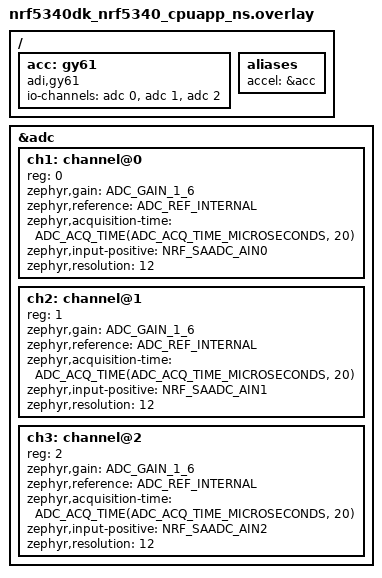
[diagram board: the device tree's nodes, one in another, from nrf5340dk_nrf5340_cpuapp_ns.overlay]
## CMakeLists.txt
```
cmake_minimum_required(VERSION 3.20.0)

find_package(Zephyr REQUIRED HINTS $ENV{ZEPHYR_BASE})

project(accel_sensor)

target_sources(app PRIVATE src/main.c)
target_sources(app PRIVATE src/acc_service.c)
target_sources(app PRIVATE src/acc_sensor.c)

# Please let this help with the sensor devicetree
set (DTS_ROOT "dts")
```

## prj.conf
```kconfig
CONFIG_SENSOR=y
CONFIG_DK_LIBRARY=y
#CONFIG_ADXL355=y

CONFIG_LOG=y
CONFIG_CBPRINTF_FP_SUPPORT=y

CONFIG_BT=y
CONFIG_BT_PERIPHERAL=y
CONFIG_BT_DEVICE_NAME="Accelerometer"

CONFIG_SYSTEM_WORKQUEUE_STACK_SIZE=2048
CONFIG_MAIN_STACK_SIZE=2048
```

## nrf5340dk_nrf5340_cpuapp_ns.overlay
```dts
// help I'm lost

/ {
    acc: gy61 {
        status = "okay";
        compatible = "adi,gy61";
        //label = "gy61";
        io-channels = <&adc 0>, <&adc 1>, <&adc 2>;
    };

    aliases {
        accel = &acc;
    };
};

&adc {
    status = "okay";
    #address-cells = <1>;
    #size-cells = <0>;

    ch1: channel@0 {
        status = "okay";
        reg = <0>;
        zephyr,gain = "ADC_GAIN_1_6";
        zephyr,reference = "ADC_REF_INTERNAL";
        zephyr,acquisition-time = <ADC_ACQ_TIME(ADC_ACQ_TIME_MICROSECONDS, 20)>;
        zephyr,input-positive = <NRF_SAADC_AIN0>;
        zephyr,resolution = <12>;
    };

    ch2: channel@1 {
        status = "okay";
        reg = <1>;
        zephyr,gain = "ADC_GAIN_1_6";
        zephyr,reference = "ADC_REF_INTERNAL";
        zephyr,acquisition-time = <ADC_ACQ_TIME(ADC_ACQ_TIME_MICROSECONDS, 20)>;
        zephyr,input-positive = <NRF_SAADC_AIN1>;
        zephyr,resolution = <12>;
    };

    ch3: channel@2 {
        status = "okay";
        reg = <2>;
        zephyr,gain = "ADC_GAIN_1_6";
        zephyr,reference = "ADC_REF_INTERNAL";
        zephyr,acquisition-time = <ADC_ACQ_TIME(ADC_ACQ_TIME_MICROSECONDS, 20)>;
        zephyr,input-positive = <NRF_SAADC_AIN2>;
        zephyr,resolution = <12>;
    };
};    
```

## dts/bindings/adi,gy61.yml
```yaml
description: "A crappy attempt at an accelerometer sensor device."

compatible: "adi,gy61"

properties:
  status:
    required: true
    type: string
  io-channels:
    required: true
    type: phandle-array
#  x-chan:
#    required: true
#    type: phandle
#  y-chan:
#    required: true
#    type: phandle
#  z-chan:
#    required: true
#    type: phandle
```

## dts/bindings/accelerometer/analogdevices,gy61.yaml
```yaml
description: "A crappy attempt at an accelerometer sensor device."

compatible: "analogdevices,gy61"

#properties:
#  sensor:
#    required: true
#    x_chan:
#      required: true
#    y_chan:
#      required: true
#    z_chan:
#      required: true
```

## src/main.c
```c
#include <stdio.h>
#include <stdlib.h>

#include <zephyr/device.h>
#include <zephyr/devicetree.h>
#include <zephyr/sys/util_macro.h>
#include <zephyr/kernel.h>

#include <dk_buttons_and_leds.h>

#include "acc_service.h"

// How often advertisements are sent out (in units of 0.625 milliseconds, equates to 500 milliseconds)
#define ADVERTISING_INTERVAL 800

#define DEVICE_NAME CONFIG_BT_DEVICE_NAME
#define DEVICE_NAME_LENGTH (sizeof(DEVICE_NAME) - 1)

#define STATUS_LED DK_LED1
#define CONNECTION_LED DK_LED2
#define DATA_BUTTON DK_BTN1_MSK

// Data for the thread running the measurements
#define STACKSIZE 1024
#define PRIORITY 7

#define BLINK_INTERVAL 500
#define MEASUREMENT_INTERVAL 5000


// 
static const struct bt_data advertisement_data[] = {
    BT_DATA_BYTES(BT_DATA_FLAGS, (BT_LE_AD_GENERAL | BT_LE_AD_NO_BREDR)),
    BT_DATA(BT_DATA_NAME_COMPLETE, DEVICE_NAME, DEVICE_NAME_LENGTH),
};

// 
static const struct bt_data scan_data[] = {
    BT_DATA_BYTES(BT_DATA_UUID128_ALL, sizeof(ACCELERATION_SERVICE_UUID))
};

// Advertising: can be connected to, advertises twice a second, not directed
static struct bt_le_adv_param *advertisement_parameters = BT_LE_ADV_PARAM(
    (BT_LE_ADV_OPT_CONNECTABLE | BT_LE_ADV_OPT_USE_IDENTITY),
    ADVERTISING_INTERVAL, ADVERTISING_INTERVAL + 1, NULL);

// Bluetooth setup:

// When a bluetooth connection is formed (or tried to)
static void on_connect(struct bt_conn *conn, uint8_t error)
{
    if (error) {
        printk("Something went wrong with connection, error %d.\n", error);
        return;
    }

    printk("Conncted.");
    dk_set_led_on(CONNECTION_LED);
}

// When a bluetooth connection is formed (or tried to)
static void on_disconnect(struct bt_conn *conn, uint8_t reason)
{
    printk("Disconnected, reason %d.\n", reason);
    dk_set_led_off(CONNECTION_LED);
}

// The functions that are called when a connection starts and ends
struct bt_conn_cb connection_callbacks = {
    .connected = on_connect,
    .disconnected = on_disconnect,
};

// ISR for when a button is pressed(?)
static void button_press(uint32_t state, uint32_t change)
{
    if (change & DATA_BUTTON) {
        read_and_indicate();
        
        // Debounce
        k_sleep(K_MSEC(1));
    }
}

// Setup of advertising and hardware, then blinking a led
int main(void)
{
    bool blink_timer = 1;
    int error;

    printk("Setting up the device.\n");

    // Led setup
    error = dk_leds_init();
    if (error) {
        printk("Led setup failed, error code %d.\n", error);
        return -1;
    }
    printk("Leds initialized.\n");

    // Button setup
    error = dk_buttons_init(button_press);
    if (error) {
        printk("Button setup failed, error code %d.\n", error);
        return -1;
    }
    printk("Buttons initialized.\n");

    // Bluetooth initialization
    error = bt_enable(NULL);
    if (error) {
        printk("Bluetooth setup failed, error code %d.\n", error);
        return -1;
    }
    printk("Bluetooth initialized.\n");

    // Bluetooth startup
    error = bt_le_adv_start(advertisement_parameters, advertisement_data, ARRAY_SIZE(advertisement_data),
        scan_data, ARRAY_SIZE(scan_data));
    if (error) {
        printk("Bluetooth startup failed, error code %d.\n", error);
        return -1;
    }
    printk("Bluetooth started.\n");

    printk("Device set up succesfully.\n");
    
    // Blink the status led to let people know the device is on and running as it should
    while (1) {
        dk_set_led(STATUS_LED, (blink_timer = blink_timer ? 0 : 1));
        k_sleep(K_MSEC(BLINK_INTERVAL));
    }
}

// A separate thread to take measurements independetly of the main loop
void measurement_thread(void)
{
    int error = initialize_accelerometer();
    if (error) {
        printk("Failed to initialize accelerometer, error code %d.\n", error);
        return;
    }
    
    while (1) {
        read_and_notify();
        k_sleep(K_MSEC(MEASUREMENT_INTERVAL));
    }
}

K_THREAD_DEFINE(thread_id, STACKSIZE, measurement_thread, NULL, NULL, NULL, PRIORITY, 0, 0);
```

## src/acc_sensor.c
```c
#include "acc_sensor.h"

#define ACCELEROMETER DT_ALIAS(accel)
#if DT_NODE_HAS_STATUS(ACCELEROMETER, okay)
const struct device *const acc_device =  DEVICE_DT_GET(ACCELEROMETER);
#else
#error "No accelerometer node"
#endif

static const struct adc_dt_spec channels[] = {
    ADC_DT_SPEC_GET_BY_IDX(DT_PATH(gy61), 0),
    ADC_DT_SPEC_GET_BY_IDX(DT_PATH(gy61), 1),
    ADC_DT_SPEC_GET_BY_IDX(DT_PATH(gy61), 2)
};

static int calculate_direction(struct AccelerationData *data);
static int channel_print(void);
static int sequence_print(struct adc_sequence sequence);


int initialize_accelerometer(void) 
{
    int err = 0;

    for (int i = 0; i < ARRAY_SIZE(channels); i++) {
		if (!device_is_ready(channels[i].dev)) {
			printk("Channel %d isn't ready?\n", i);
			return -1;
		}

		err = adc_channel_setup_dt(&channels[i]);
		if (err < 0) {
			printk("Channel %d failed with setup, err %d.\n", i, err);
			return -1;
		}
	}

    channel_print();

    return 0;
}

int read_data(struct AccelerationData *data) 
{
    data->x = 0;
    data->y = 0;
    data->z = 0;
    data->direction = 0;
    
    int16_t temp = 0;
    int32_t large_temp = 0;
    struct adc_sequence temp_seq = {
        .buffer = &temp,
        .buffer_size = sizeof(temp)
    };
    int err;

    for (int i = 0; sizeof(channels); i++) {        
        // Setup of temp_seq
        err = adc_sequence_init_dt(&channels[i], &temp_seq);
        if (err < 0) {
            printk("Failed to set up channel %d, aborting measurement.Err %d.\n", i+1, err);
            return err;
        }

        sequence_print(temp_seq);

        // Something something read request
        err = adc_read(channels[i].dev, &temp_seq);
        if (err < 0) {
            printk("Failed to read channel %d, aborting measurement.Err %d.\n", i+1, err);
            return err;
        }

        // Converts whatever magic happened inside the computer to a millivolt value
        // (accelerometer should provide ~1600 for still and ~1900 for the side affected by gravity)
        err = adc_raw_to_millivolts_dt(&channels[i], &large_temp);
        if (err < 0) {
            printk("Error with parsing channel %d, aborting measurement.\n", i+1);
            return err;
        }

        // Assign data to the bundle of measurements
        switch (i) {
            case 0:
                data->x = temp;
                break;
            case 1:
                data->y = temp;
                break;
            case 2:
                data->z = temp;
                break;
        }
    }

    calculate_direction(data);

    return 0;
}

static int calculate_direction(struct AccelerationData *data)
{
    data->direction = 0;
    return 0;
}


static int channel_print(void) 
{
    printk("channel_print():\n");
    for (int i = 0; i < 3; i++) {
        printk("adc_dt_spec structure, channel %d = \n", i);
        printk("Device pointer = %p\n", channels[i].dev);
        printk("Channel Id = %d\n", channels[i].channel_id);
    }

    return 0;
}

static int sequence_print(struct adc_sequence sequence) 
{
    printk("sequence_print():\n");
    printk("Channels: %d\n", sequence.channels);
    printk("Buffer: %p\n", sequence.buffer);
    printk("Buffer size: %d\n", sequence.buffer_size);
    printk("Resolution: %d\n", sequence.resolution);
    printk("Oversampling: %d\n", sequence.oversampling);

    return 0;
}
```

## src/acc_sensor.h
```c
#ifndef ACC_SENSOR_H
#define ACC_SENSOR_H

#include <stdint.h>
#include <zephyr/device.h>
#include <zephyr/devicetree.h>
#include <zephyr/kernel.h>
#include <zephyr/drivers/adc.h>

struct AccelerationData {
    int16_t x;
    int16_t y;
    int16_t z;
    int16_t direction;
};

// Accelerometer setup and a means of getting a reading
int initialize_accelerometer(void);
struct AccelerationData read_data(void);

#endif
```

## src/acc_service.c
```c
#include "acc_service.h"

// Whether notification messages should get sent
static bool notify_enabled;
static bool indicate_enabled;
// A collection of parameters concerning indication settings
static struct bt_gatt_indicate_params indication_parameters;

// Holds current reading data
struct AccelerationData reading;

// Declarations
static int accelerometer_notification(void);
static int accelerometer_indication(void);
static void indication_callback(struct bt_conn *connection, struct bt_gatt_indicate_params *parameters, uint8_t error);


int read_and_notify(void) 
{
    reading = read_data();
    if (reading.direction == 0) {
        //printk("read_and_notify(): error with getting a reading. No notification sent.\n");
        return -1;
    }

    int err = accelerometer_notification();
    if (err < 0) {
        //printk("read_and_notify(): error %d sending notification.\n", err);
        return err;
    }
    return 0;
}

int read_and_indicate(void) 
{
    reading = read_data();
    if (reading.direction == 0) {
        //printk("read_and_indicate(): error with getting a reading. No indication sent.\n");
        return -1;
    }

    int err = accelerometer_indication();
    if (err < 0) {
        //printk("read_and_indicate(): error %d sending indication.\n", err);
        return err;
    }
    return 0;
}

// Internal workings below

// What gets called when the device you're connected to wants to change notification settings(?)
static void notification_configuration_change(const struct bt_gatt_attr *attributes, uint16_t value)
{
    notify_enabled = (value == BT_GATT_CCC_NOTIFY);

    printk("Notification configuration changed, now %d.\n", notify_enabled);
}

// What gets called when the device you're connected to wants to change indication settings(?)
static void indication_configuration_change(const struct bt_gatt_attr *attributes, uint16_t value)
{
    indicate_enabled = (value == BT_GATT_CCC_INDICATE);

    printk("Indication configuration changed, now %d.\n", indicate_enabled);
}

// Setting up the service and attributes holding our data
BT_GATT_SERVICE_DEFINE(
    accelerometer, 
    // Sets up the service for acceleration measurements
    BT_GATT_PRIMARY_SERVICE(ACCELERATION_SERVICE_UUID),
    //
    BT_GATT_CHARACTERISTIC(ACCELERATION_NOTIFICATION_UUID, BT_GATT_CHRC_NOTIFY, BT_GATT_PERM_READ, NULL, NULL, &reading),
    BT_GATT_CCC(notification_configuration_change, BT_GATT_PERM_READ | BT_GATT_PERM_WRITE),

    BT_GATT_CHARACTERISTIC(ACCELERATION_INDICATION_UUID, BT_GATT_CHRC_INDICATE, BT_GATT_PERM_READ, NULL, NULL, &reading),
    BT_GATT_CCC(indication_configuration_change, BT_GATT_PERM_READ | BT_GATT_PERM_WRITE),
);

static int accelerometer_notification(void)
{
    if (!notify_enabled) {
        return -EACCES;
    }
    // Looks up the acceleration values characteristic (or attribute?) based on its assigned ID
    return bt_gatt_notify(NULL, bt_gatt_find_by_uuid(NULL, 0, ACCELERATION_NOTIFICATION_UUID), &reading, sizeof(reading));
}

static int accelerometer_indication(void)
{
    if(!indicate_enabled) {
        return -EACCES;
    }

    indication_parameters.attr = bt_gatt_find_by_uuid(NULL, 0, ACCELERATION_INDICATION_UUID);
	indication_parameters.func = indication_callback;
	indication_parameters.destroy = NULL;
	indication_parameters.data = &reading;
	indication_parameters.len = sizeof(reading);

    return bt_gatt_indicate(NULL, &indication_parameters);
}

// Gets called when an indication has been sent and is answered to
static void indication_callback(struct bt_conn *connection, struct bt_gatt_indicate_params *parameters, uint8_t error) 
{
    printk("Indication callback\n");
}
```

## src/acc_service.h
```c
#ifndef ACC_SERVICE_H
#define ACC_SERVICE_H

#include <stdbool.h>
#include <zephyr/bluetooth/gatt.h>
#include <zephyr/logging/log.h>
#include "acc_sensor.h"

// UUIDs for our data (the whole service, x y and z directional values and the direction of the device)
#define ACCELERATION_SERVICE_UUID_VALUE BT_UUID_128_ENCODE(0xf50234f0, 0x4833, 0x42b8, 0x8d36, 0x983f06b3ee8e)
#define ACCELERATION_VALUES_UUID_VALUE BT_UUID_128_ENCODE(0xf50234f1, 0x4833, 0x42b8, 0x8d36, 0x983f06b3ee8e)
#define ACCELERATION_RESULTS_UUID_VALUE BT_UUID_128_ENCODE(0xf50234f2, 0x4833, 0x42b8, 0x8d36, 0x983f06b3ee8e)
#define ACCELERATION_DIRECTION_UUID_VALUE BT_UUID_128_ENCODE(0xf50234f3, 0x4833, 0x42b8, 0x8d36, 0x983f06b3ee8e)

#define ACCELERATION_SERVICE_UUID BT_UUID_DECLARE_128(ACCELERATION_SERVICE_UUID_VALUE)
#define ACCELERATION_VALUES_UUID BT_UUID_DECLARE_128(ACCELERATION_VALUES_UUID_VALUE)
#define ACCELERATION_RESULTS_UUID BT_UUID_DECLARE_128(ACCELERATION_RESULTS_UUID_VALUE)
#define ACCELERATION_DIRECTION_UUID BT_UUID_DECLARE_128(ACCELERATION_DIRECTION_UUID_VALUE)

void simulate_measurement(void);
void simulate_direction(void);

int accelerometer_raw_notification(void);
int accelerometer_calculated_notification(void);
int accelerometer_indication(void);

#endif
```
